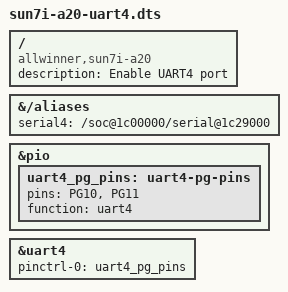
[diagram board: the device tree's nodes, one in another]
/dts-v1/;
/plugin/;

/ {
	compatible = "allwinner,sun7i-a20";
	description = "Enable UART4 port";

	fragment@0 {
		target-path = "/aliases";
		__overlay__ {
			serial4 = "/soc@1c00000/serial@1c29000";
		};
	};

	fragment@1 {
		target = <&pio>;
		__overlay__ {
			uart4_pg_pins: uart4-pg-pins {
				pins = "PG10", "PG11";
				function = "uart4";
			};
		};
	};

	fragment@2 {
		target = <&uart4>;
		__overlay__ {
			pinctrl-names = "default";
			pinctrl-0 = <&uart4_pg_pins>;
			status = "okay";
		};
	};
};
